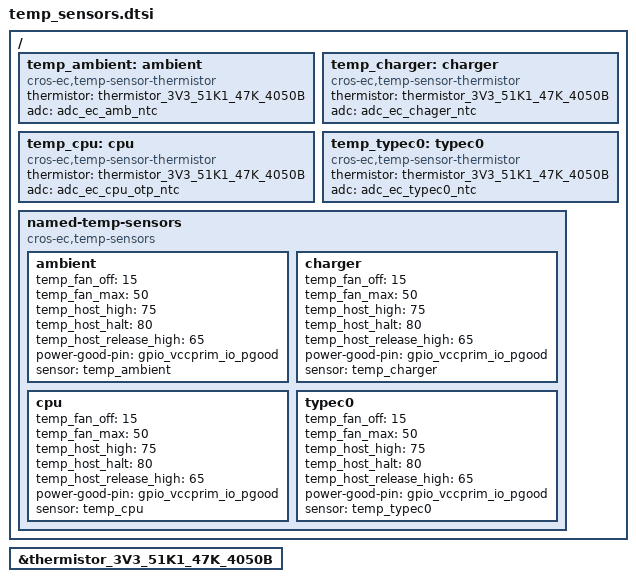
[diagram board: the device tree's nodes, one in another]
/* Copyright 2025 The ChromiumOS Authors
 * Use of this source code is governed by a BSD-style license that can be
 * found in the LICENSE file.
 */

#include <cros/thermistor/thermistor.dtsi>

/ {
	temp_ambient: ambient {
		compatible = "cros-ec,temp-sensor-thermistor";
		thermistor = <&thermistor_3V3_51K1_47K_4050B>;
		adc = <&adc_ec_amb_ntc>;
	};
	temp_charger: charger {
		compatible = "cros-ec,temp-sensor-thermistor";
		thermistor = <&thermistor_3V3_51K1_47K_4050B>;
		adc = <&adc_ec_chager_ntc>;
	};
	temp_cpu: cpu {
		compatible = "cros-ec,temp-sensor-thermistor";
		thermistor = <&thermistor_3V3_51K1_47K_4050B>;
		adc = <&adc_ec_cpu_otp_ntc>;
	};
	temp_typec0: typec0 {
		compatible = "cros-ec,temp-sensor-thermistor";
		thermistor = <&thermistor_3V3_51K1_47K_4050B>;
		adc = <&adc_ec_typec0_ntc>;
	};

	named-temp-sensors {
		compatible = "cros-ec,temp-sensors";

		ambient {
			temp_fan_off = <15>;
			temp_fan_max = <50>;
			temp_host_high = <75>;
			temp_host_halt = <80>;
			temp_host_release_high = <65>;
			power-good-pin = <&gpio_vccprim_io_pgood>;
			sensor = <&temp_ambient>;
		};
		charger {
			temp_fan_off = <15>;
			temp_fan_max = <50>;
			temp_host_high = <75>;
			temp_host_halt = <80>;
			temp_host_release_high = <65>;
			power-good-pin = <&gpio_vccprim_io_pgood>;
			sensor = <&temp_charger>;
		};
		cpu {
			temp_fan_off = <15>;
			temp_fan_max = <50>;
			temp_host_high = <75>;
			temp_host_halt = <80>;
			temp_host_release_high = <65>;
			power-good-pin = <&gpio_vccprim_io_pgood>;
			sensor = <&temp_cpu>;
		};
		typec0 {
			temp_fan_off = <15>;
			temp_fan_max = <50>;
			temp_host_high = <75>;
			temp_host_halt = <80>;
			temp_host_release_high = <65>;
			power-good-pin = <&gpio_vccprim_io_pgood>;
			sensor = <&temp_typec0>;
		};
	};
};

&thermistor_3V3_51K1_47K_4050B {
	status = "okay";
};
